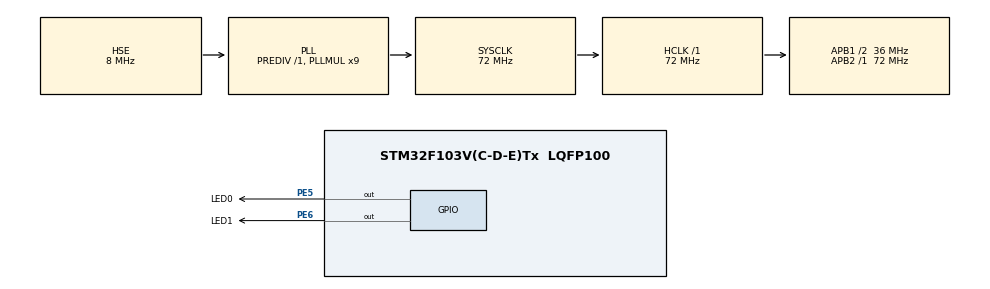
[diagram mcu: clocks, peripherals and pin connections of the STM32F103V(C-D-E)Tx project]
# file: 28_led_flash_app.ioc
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Mcu.Family=STM32F1
Mcu.Name=STM32F103V(C-D-E)Tx
Mcu.Package=LQFP100
NVIC.PriorityGroup=NVIC_PRIORITYGROUP_4
OSC_IN.Mode=HSE-External-Oscillator
OSC_IN.Signal=RCC_OSC_IN
OSC_OUT.Mode=HSE-External-Oscillator
OSC_OUT.Signal=RCC_OSC_OUT
PA13.Mode=Serial_Wire
PA13.Signal=SYS_JTMS-SWDIO
PA14.Mode=Serial_Wire
PA14.Signal=SYS_JTCK-SWCLK
PC14-OSC32_IN.Mode=LSE-External-Oscillator
PC14-OSC32_IN.Signal=RCC_OSC32_IN
PC15-OSC32_OUT.Mode=LSE-External-Oscillator
PC15-OSC32_OUT.Signal=RCC_OSC32_OUT
PE5.GPIO_Label=LED0
PE5.GPIO_PuPd=GPIO_PULLUP
PE5.GPIO_Speed=GPIO_SPEED_FREQ_HIGH
PE5.PinState=GPIO_PIN_SET
PE5.Signal=GPIO_Output
PE6.GPIO_Label=LED1
PE6.GPIO_PuPd=GPIO_PULLUP
PE6.GPIO_Speed=GPIO_SPEED_FREQ_HIGH
PE6.PinState=GPIO_PIN_SET
PE6.Signal=GPIO_Output
ProjectManager.HeapSize=0x200
ProjectManager.StackSize=0x400
ProjectManager.TargetToolchain=STM32CubeIDE
RCC.AHBFreq_Value=72000000
RCC.APB1CLKDivider=RCC_HCLK_DIV2
RCC.APB1Freq_Value=36000000
RCC.APB1TimFreq_Value=72000000
RCC.APB2Freq_Value=72000000
RCC.APB2TimFreq_Value=72000000
RCC.HCLKFreq_Value=72000000
RCC.PLLMUL=RCC_PLL_MUL9
RCC.PLLSourceVirtual=RCC_PLLSOURCE_HSE
RCC.SYSCLKFreq_VALUE=72000000
RCC.SYSCLKSource=RCC_SYSCLKSOURCE_PLLCLK
RCC.USBFreq_Value=72000000
board=custom

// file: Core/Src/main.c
/* USER CODE BEGIN Header */
/**
 ****************************************************************************************************
 * @file        main.c
 * @author      ALIENTEK
 * @brief       IAP_Flash_App code
 * @license     Copyright (C) 2012-2024, ALIENTEK
 ****************************************************************************************************
 * @attention
 *
 * platform     : ALIENTEK M100-STM32F103 board
 * website      : www.alientek.com
 * forum        : www.openedv.com/forum.php
 *
 * change logs  :
 * version      data         notes
 * V1.0         20240409     the first version
 *
 ****************************************************************************************************
 */
/* USER CODE END Header */
#include "main.h"
#include "gpio.h"

/* USER CODE BEGIN Includes */
#include "../../BSP/LED/led.h"
/* USER CODE END Includes */

void SystemClock_Config(void);
/* USER CODE BEGIN PFP */
void sys_nvic_set_vector_table(uint32_t baseaddr, uint32_t offset)
{
    /* 设置NVIC的向量表偏移寄存器,VTOR低9位保留,即[8:0]保留 */
    SCB->VTOR = baseaddr | (offset & (uint32_t)0xFFFFFE00);
}

/* USER CODE END PFP */

int main(void)
{
  /* USER CODE BEGIN 1 */
  /* The vector table offset register of NVIC is set,
   * and the lower 9 bits of VTOR are reserved, that is, [8:0] reserved */
   SCB->VTOR = FLASH_BASE | (0x10000 & (uint32_t)0xFFFFFE00);
   //sys_nvic_set_vector_table(FLASH_BASE, 0x10000);
  /* USER CODE END 1 */

  /* MCU Configuration--------------------------------------------------------*/

  /* Reset of all peripherals, Initializes the Flash interface and the Systick. */
  HAL_Init();

  /* Configure the system clock */
  SystemClock_Config();

  /* Initialize all configured peripherals */
  MX_GPIO_Init();

  /* Infinite loop */
  /* USER CODE BEGIN WHILE */
  while (1)
  {
	  LED0(0);     /* turn on LED0 */
	  LED1(1);     /* turn off LED1 */
	  HAL_Delay(100);
	  LED0(1);     /* turn off LED0 */
	  LED1(0);     /* turn on LED1 */
	  HAL_Delay(100);
    /* USER CODE END WHILE */

  }
}

void SystemClock_Config(void)
{
  RCC_OscInitTypeDef RCC_OscInitStruct = {0};
  RCC_ClkInitTypeDef RCC_ClkInitStruct = {0};

  /** Initializes the RCC Oscillators according to the specified parameters
  * in the RCC_OscInitTypeDef structure.
  */
  RCC_OscInitStruct.OscillatorType = RCC_OSCILLATORTYPE_HSE;
  RCC_OscInitStruct.HSEState = RCC_HSE_ON;
  RCC_OscInitStruct.HSEPredivValue = RCC_HSE_PREDIV_DIV1;
  RCC_OscInitStruct.HSIState = RCC_HSI_ON;
  RCC_OscInitStruct.PLL.PLLState = RCC_PLL_ON;
  RCC_OscInitStruct.PLL.PLLSource = RCC_PLLSOURCE_HSE;
  RCC_OscInitStruct.PLL.PLLMUL = RCC_PLL_MUL9;
  if (HAL_RCC_OscConfig(&RCC_OscInitStruct) != HAL_OK)
  {
    Error_Handler();
  }

  /** Initializes the CPU, AHB and APB buses clocks
  */
  RCC_ClkInitStruct.ClockType = RCC_CLOCKTYPE_HCLK|RCC_CLOCKTYPE_SYSCLK
                              |RCC_CLOCKTYPE_PCLK1|RCC_CLOCKTYPE_PCLK2;
  RCC_ClkInitStruct.SYSCLKSource = RCC_SYSCLKSOURCE_PLLCLK;
  RCC_ClkInitStruct.AHBCLKDivider = RCC_SYSCLK_DIV1;
  RCC_ClkInitStruct.APB1CLKDivider = RCC_HCLK_DIV2;
  RCC_ClkInitStruct.APB2CLKDivider = RCC_HCLK_DIV1;

  if (HAL_RCC_ClockConfig(&RCC_ClkInitStruct, FLASH_LATENCY_2) != HAL_OK)
  {
    Error_Handler();
  }
}

void Error_Handler(void)
{
  __disable_irq();
  while (1)
  {
  }
}
